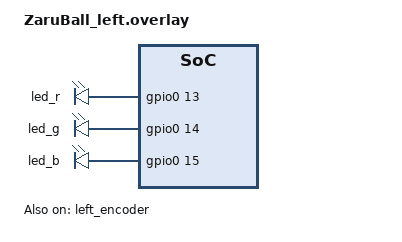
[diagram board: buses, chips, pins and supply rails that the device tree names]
#include "ZaruBall.dtsi"

&kscan0 {
    col-gpios = 
        <&xiao_d 10 GPIO_ACTIVE_HIGH>,
        <&xiao_d 9 GPIO_ACTIVE_HIGH>,
        <&xiao_d 8 GPIO_ACTIVE_HIGH>,
        <&xiao_d 7 GPIO_ACTIVE_HIGH>,
        <&gpio0 9 GPIO_ACTIVE_HIGH>,
        <&gpio0 10 GPIO_ACTIVE_HIGH>,
        <&xiao_d 4 GPIO_ACTIVE_HIGH>;
};

&left_encoder {
    status = "okay";
};
/{
    leds {
        compatible = "gpio-leds";

        led_r: led_red {
            gpios = <&gpio0 13 GPIO_ACTIVE_HIGH>;
        };

        led_g: led_green {
            gpios = <&gpio0 14 GPIO_ACTIVE_HIGH>;
        };

        led_b: led_blue {
            gpios = <&gpio0 15 GPIO_ACTIVE_HIGH>;
        };
    };

    aliases {
        led_red = &led_r;
        led_green = &led_g;
        led_blue = &led_b;
    };
};
